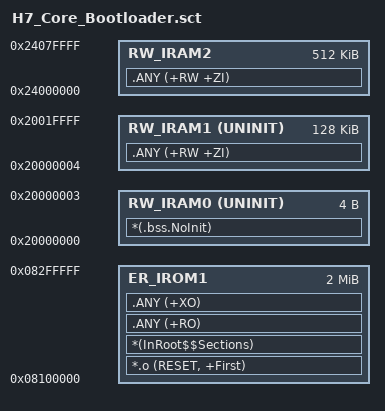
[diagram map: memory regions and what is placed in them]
; *************************************************************
; *** Scatter-Loading Description File generated by uVision ***
; *************************************************************

LR_IROM1 0x08100000 0x00200000  {    ; load region size_region
  ER_IROM1 0x08100000 0x00200000  {  ; load address = execution address
   *.o (RESET, +First)
   *(InRoot$$Sections)
   .ANY (+RO)
   .ANY (+XO)
  }
	
	RW_IRAM0 0x20000000 UNINIT 0x00000004  {  ; RW data
   *(.bss.NoInit)
  }
  RW_IRAM1 0x20000004 UNINIT 0x0001FFFC  {  ; RW data
   .ANY (+RW +ZI)
  }
  RW_IRAM2 0x24000000 0x00080000  {
   .ANY (+RW +ZI)
  }
}

